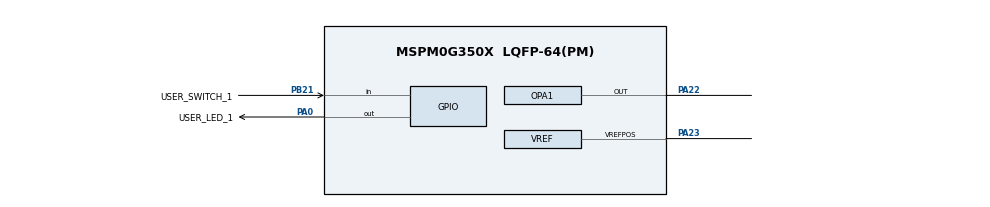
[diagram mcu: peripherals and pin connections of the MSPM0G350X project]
// @cliArgs --device "MSPM0G350X" --package "LQFP-64(PM)" --part "Default"
// @cliArgs --board /ti/boards/LP_MSPM0G3507 --rtos nortos

/**
 * Import the modules used in this configuration.
 */
const COMP   = scripting.addModule("/ti/driverlib/COMP", {}, false);
const COMP1  = COMP.addInstance();
const GPIO   = scripting.addModule("/ti/driverlib/GPIO", {}, false);
const GPIO1  = GPIO.addInstance();
const GPIO2  = GPIO.addInstance();
const OPA    = scripting.addModule("/ti/driverlib/OPA", {}, false);
const OPA1   = OPA.addInstance();
const SYSCTL = scripting.addModule("/ti/driverlib/SYSCTL");
const TIMER  = scripting.addModule("/ti/driverlib/TIMER", {}, false);
const TIMER1 = TIMER.addInstance();
const VREF   = scripting.addModule("/ti/driverlib/VREF");

/**
 * Write custom configuration values to the imported modules.
 */
COMP1.$name              = "COMP_0";
COMP1.vSource            = "DL_COMP_REF_SOURCE_VDDA_DAC";
COMP1.controlSelect      = "DL_COMP_DAC_CONTROL_SW";
COMP1.peripheral.$assign = "COMP0";

const Board = scripting.addModule("/ti/driverlib/Board", {}, false);

GPIO1.$name                          = "GPIO_LEDS";
GPIO1.associatedPins[0].$name        = "USER_LED_1";
GPIO1.associatedPins[0].assignedPort = "PORTA";
GPIO1.associatedPins[0].assignedPin  = "0";
GPIO1.associatedPins[0].initialValue = "SET";
GPIO1.associatedPins[0].pin.$assign  = "PA0";

GPIO2.$name                              = "GPIO_SWITCHES";
GPIO2.associatedPins[0].assignedPort     = "PORTB";
GPIO2.associatedPins[0].assignedPin      = "21";
GPIO2.associatedPins[0].$name            = "USER_SWITCH_1";
GPIO2.associatedPins[0].direction        = "INPUT";
GPIO2.associatedPins[0].internalResistor = "PULL_UP";
GPIO2.associatedPins[0].interruptEn      = true;
GPIO2.associatedPins[0].polarity         = "RISE_FALL";
GPIO2.associatedPins[0].pin.$assign      = "PB21";

OPA1.$name                     = "OPA_0";
OPA1.cfg0PSELChannel           = "DAC8_OUT";
OPA1.cfg0NSELChannel           = "RTOP";
OPA1.cfg0OutputPin             = "ENABLED";
OPA1.cfg0Chop                  = "STANDARD";
OPA1.advBW                     = "HIGH";
OPA1.advRRI                    = true;
OPA1.peripheral.$assign        = "OPA0";
OPA1.peripheral.OutPin.$assign = "PA22";

SYSCTL.MFCLKEn = true;
SYSCTL.forceDefaultClkConfig = true;

TIMER1.$name              = "TIMER_0";
TIMER1.timerMode          = "PERIODIC";
TIMER1.timerClkDiv        = 8;
TIMER1.timerClkPrescale   = 128;
TIMER1.interrupts         = ["ZERO"];
TIMER1.timerPeriod        = "500ms";
TIMER1.peripheral.$assign = "TIMG0";

VREF.advClockConfigEnable          = true;
VREF.checkVREFReady                = true;
VREF.peripheral.$assign            = "VREF";
VREF.peripheral.vrefPosPin.$assign = "PA23";
